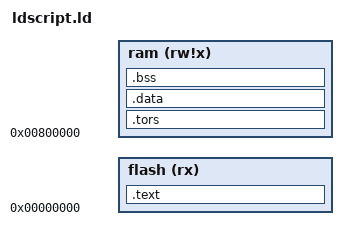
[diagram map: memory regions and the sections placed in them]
/* Default linker script, for normal executables */
OUTPUT_FORMAT("elf32-ft32")
OUTPUT_ARCH(ft32)
SEARCH_DIR("/opt/ft32/ft32-elf/lib");
/* Allow the command line to override the memory region sizes.  */
__PMSIZE = DEFINED(__PMSIZE)  ? __PMSIZE : 256K;
__RAMSIZE = DEFINED(__RAMSIZE) ? __RAMSIZE : 64K;
MEMORY
{
  flash     (rx)   : ORIGIN = 0,        LENGTH = __PMSIZE
  ram       (rw!x) : ORIGIN = 0x800000, LENGTH = __RAMSIZE
}

SECTIONS
{
  .text :
  {
    *(.crt0*)
    *(.text*)
    *(.strings)
    *(._pm*)
    *(.init)
    *(.fini)
     _etext = . ;
    . = ALIGN(4);
  }  > flash
  
  .tors :
  {
    ___ctors = . ;
    *(.ctors)
    ___ctors_end = . ;
    ___dtors = . ;
    *(.dtors)
    ___dtors_end = . ;
    . = ALIGN(4);
  } > ram
  
  .data	  : AT (ADDR (.text) + SIZEOF (.text))
  {
  _sdata = .;
    *(.data)
    *(.data*)    /* +++++ NEW ++++++ */
    *(.rodata)
    *(.rodata*)
     _edata = . ;
  }  > ram
  
  .bss  SIZEOF(.data) + ADDR(.data) :
  {
     _bss_start = . ;
    *(.bss)
    *(.bss*)    /* +++++ NEW ++++++ */
    *(COMMON)
     _end = . ;
  }  > ram
   __data_load_start = LOADADDR(.data);
   __data_load_end = __data_load_start + SIZEOF(.data);
   
   
  .stab 0 (NOLOAD) :
  {
    *(.stab)
  }
  .stabstr 0 (NOLOAD) :
  {
    *(.stabstr)
  }
}
